AUTOSAR XML (schema 4-0-3)
package /ComponentTypes
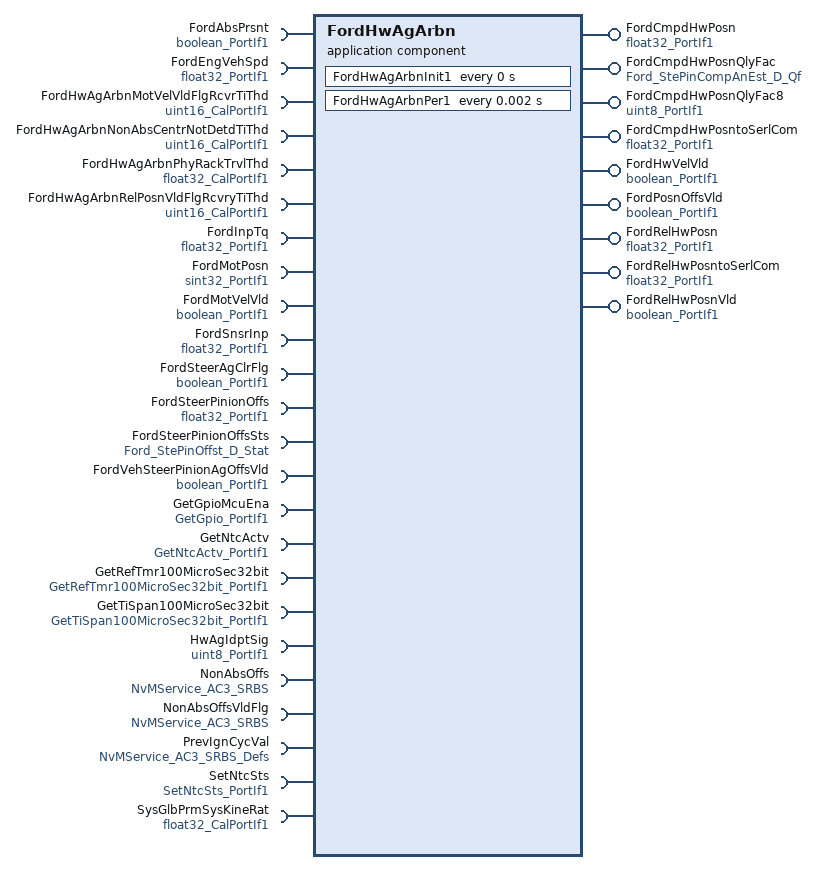
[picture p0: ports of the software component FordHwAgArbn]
  application sw component type FordHwAgArbn
    9 x provide port:
      FordCmpdHwPosn: nonqueued-sender-com-spec{data-element=Val, init-value=0}, provided-interface=float32_PortIf1
      FordCmpdHwPosnQlyFac: nonqueued-sender-com-spec{data-element=Ford_StePinCompAnEst_D_Qf, init-value=1}, provided-interface=Ford_StePinCompAnEst_D_Qf
      FordCmpdHwPosnQlyFac8: nonqueued-sender-com-spec{data-element=Val, init-value=1}, provided-interface=uint8_PortIf1
      FordCmpdHwPosntoSerlCom: nonqueued-sender-com-spec{data-element=Val, init-value=0}, provided-interface=float32_PortIf1
      FordHwVelVld: nonqueued-sender-com-spec{data-element=Logl, init-value=0}, provided-interface=boolean_PortIf1
      FordPosnOffsVld: nonqueued-sender-com-spec{data-element=Logl, init-value=0}, provided-interface=boolean_PortIf1
      FordRelHwPosn: nonqueued-sender-com-spec{data-element=Val, init-value=0}, provided-interface=float32_PortIf1
      FordRelHwPosntoSerlCom: nonqueued-sender-com-spec{data-element=Val, init-value=0}, provided-interface=float32_PortIf1
      FordRelHwPosnVld: nonqueued-sender-com-spec{data-element=Logl, init-value=0}, provided-interface=boolean_PortIf1
    24 x require port:
      FordAbsPrsnt: nonqueued-receiver-com-spec{data-element=Logl, filter=data-filter-type=ALWAYS, init-value=0}, required-interface=boolean_PortIf1
      FordEngVehSpd: nonqueued-receiver-com-spec{data-element=Val, filter=data-filter-type=ALWAYS, init-value=0}, required-interface=float32_PortIf1
      FordHwAgArbnMotVelVldFlgRcvrTiThd: parameter-require-com-spec{init-value=30000, parameter=Val}, required-interface=uint16_CalPortIf1
      FordHwAgArbnNonAbsCentrNotDetdTiThd: parameter-require-com-spec{init-value=30000, parameter=Val}, required-interface=uint16_CalPortIf1
      FordHwAgArbnPhyRackTrvlThd: parameter-require-com-spec{init-value=65535, parameter=Val}, required-interface=float32_CalPortIf1
      FordHwAgArbnRelPosnVldFlgRcvryTiThd: parameter-require-com-spec{init-value=0, parameter=Val}, required-interface=uint16_CalPortIf1
      FordInpTq: nonqueued-receiver-com-spec{data-element=Val, filter=data-filter-type=ALWAYS, init-value=0}, required-interface=float32_PortIf1
      FordMotPosn: nonqueued-receiver-com-spec{data-element=Val, filter=data-filter-type=ALWAYS}, required-interface=sint32_PortIf1
      FordMotVelVld: nonqueued-receiver-com-spec{data-element=Logl, filter=data-filter-type=ALWAYS, init-value=0}, required-interface=boolean_PortIf1
      FordSnsrInp: nonqueued-receiver-com-spec{data-element=Val, filter=data-filter-type=ALWAYS, init-value=0}, required-interface=float32_PortIf1
      FordSteerAgClrFlg: nonqueued-receiver-com-spec{data-element=Logl, filter=data-filter-type=ALWAYS, init-value=0}, required-interface=boolean_PortIf1
      FordSteerPinionOffs: nonqueued-receiver-com-spec{data-element=Val, filter=data-filter-type=ALWAYS, init-value=0}, required-interface=float32_PortIf1
      FordSteerPinionOffsSts: nonqueued-receiver-com-spec{data-element=Ford_StePinOffst_D_Stat, filter=data-filter-type=ALWAYS, init-value=0}, required-interface=Ford_StePinOffst_D_Stat
      FordVehSteerPinionAgOffsVld: nonqueued-receiver-com-spec{data-element=Logl, filter=data-filter-type=ALWAYS, init-value=0}, required-interface=boolean_PortIf1
      GetGpioMcuEna: client-com-spec=Oper, required-interface=GetGpio_PortIf1
      GetNtcActv: client-com-spec=Oper, required-interface=GetNtcActv_PortIf1
      GetRefTmr100MicroSec32bit: client-com-spec=Oper, required-interface=GetRefTmr100MicroSec32bit_PortIf1
      GetTiSpan100MicroSec32bit: client-com-spec=Oper, required-interface=GetTiSpan100MicroSec32bit_PortIf1
      HwAgIdptSig: nonqueued-receiver-com-spec{data-element=Val, filter=data-filter-type=ALWAYS, init-value=2}, required-interface=uint8_PortIf1
      NonAbsOffs: required-com-specs=[EraseBlock, GetErrorStatus, InvalidateNvBlock, ReadBlock, SetRamBlockStatus, WriteBlock], required-interface=NvMService_AC3_SRBS
      NonAbsOffsVldFlg: required-com-specs=[EraseBlock, GetErrorStatus, InvalidateNvBlock, ReadBlock, SetRamBlockStatus, WriteBlock], required-interface=NvMService_AC3_SRBS
      PrevIgnCycVal: required-com-specs=[EraseBlock, GetErrorStatus, InvalidateNvBlock, ReadBlock, RestoreBlockDefaults, SetRamBlockStatus, WriteBlock], required-interface=NvMService_AC3_SRBS_Defs
      SetNtcSts: client-com-spec=Oper, required-interface=SetNtcSts_PortIf1
      SysGlbPrmSysKineRat: parameter-require-com-spec{init-value=22, parameter=Val}, required-interface=float32_CalPortIf1
    behavior FordHwAgArbn_InternalBehavior
      ar-typed-per-instance-memorys:
        14 x data, all with sw-calibration-access=READ-ONLY:
          FirstTranVldFlg: type=boolean
          FordCmpdHwPosnPrev: type=float32
          FordCmpdHwPosnQlyFacPrev: type=Ford_StePinCompAnEst_D_Qf
          FordSteerPinionOffsStsPrev: type=Ford_StePinOffst_D_Stat
          MotVelVldTrueTi: type=uint32
          NoDataExistFlg: type=boolean
          NonAbsCentrNotDetdTi: type=uint32
          NonAbsOffs: type=float32
          NonAbsOffsVldFlg: type=boolean
          PrevIgnCycVal: type=float32
          RelHwPosnPrev: type=float32
          RelHwPosnVld: type=boolean
          RelPosnLossFlg: type=boolean
          RelPosnVldFlgRcvryTi: type=uint32
      timing event FordHwAgArbn_InitEvent: start-on-event=FordHwAgArbnInit1, period=0
      timing event TMT_FordHwAgArbnPer1: start-on-event=FordHwAgArbnPer1, period=0.002
      explicit-inter-runnable-variables:
        data FordSnsrOutp: type=float32, init-value=0
      port-api-options:
        enable-take-address=false, indirect-api=false, port=FordAbsPrsnt
        enable-take-address=false, indirect-api=false, port=FordCmpdHwPosn
        enable-take-address=false, indirect-api=false, port=FordCmpdHwPosnQlyFac
        enable-take-address=false, indirect-api=false, port=FordCmpdHwPosnQlyFac8
        enable-take-address=false, indirect-api=false, port=FordCmpdHwPosntoSerlCom
        enable-take-address=false, indirect-api=false, port=FordEngVehSpd
        enable-take-address=false, indirect-api=false, port=FordHwAgArbnMotVelVldFlgRcvrTiThd
        enable-take-address=false, indirect-api=false, port=FordHwAgArbnNonAbsCentrNotDetdTiThd
        enable-take-address=false, indirect-api=false, port=FordHwAgArbnPhyRackTrvlThd
        enable-take-address=false, indirect-api=false, port=FordHwAgArbnRelPosnVldFlgRcvryTiThd
        enable-take-address=false, indirect-api=false, port=FordHwVelVld
        enable-take-address=false, indirect-api=false, port=FordInpTq
        enable-take-address=false, indirect-api=false, port=FordMotPosn
        enable-take-address=false, indirect-api=false, port=FordMotVelVld
        enable-take-address=false, indirect-api=false, port=FordPosnOffsVld
        enable-take-address=false, indirect-api=false, port=FordRelHwPosn
        enable-take-address=false, indirect-api=false, port=FordRelHwPosntoSerlCom
        enable-take-address=false, indirect-api=false, port=FordRelHwPosnVld
        enable-take-address=false, indirect-api=false, port=FordSnsrInp
        enable-take-address=false, indirect-api=false, port=FordSteerAgClrFlg
        enable-take-address=false, indirect-api=false, port=FordSteerPinionOffs
        enable-take-address=false, indirect-api=false, port=FordSteerPinionOffsSts
        enable-take-address=false, indirect-api=false, port=FordVehSteerPinionAgOffsVld
        enable-take-address=false, indirect-api=false, port=GetGpioMcuEna
        enable-take-address=false, indirect-api=false, port=GetNtcActv
        enable-take-address=false, indirect-api=false, port=GetRefTmr100MicroSec32bit
        enable-take-address=false, indirect-api=false, port=GetTiSpan100MicroSec32bit
        enable-take-address=false, indirect-api=false, port=HwAgIdptSig
        enable-take-address=false, indirect-api=false, port=NonAbsOffs
        enable-take-address=false, indirect-api=false, port=NonAbsOffsVldFlg
        enable-take-address=false, indirect-api=false, port=PrevIgnCycVal
        enable-take-address=false, indirect-api=false, port=SetNtcSts
        enable-take-address=false, indirect-api=false, port=SysGlbPrmSysKineRat
      runnable FordHwAgArbnInit1
        7 x sync call, all with timeout=0:
          SC_GetRefTmr100MicroSec32bit_Oper: operation=GetRefTmr100MicroSec32bit.Oper
          SC_NonAbsOffs_GetErrorStatus: operation=NonAbsOffs.GetErrorStatus
          SC_NonAbsOffs_SetRamBlockStatus: operation=NonAbsOffs.SetRamBlockStatus
          SC_NonAbsOffsVldFlg_GetErrorStatus: operation=NonAbsOffsVldFlg.GetErrorStatus
          SC_NonAbsOffsVldFlg_SetRamBlockStatus: operation=NonAbsOffsVldFlg.SetRamBlockStatus
          SC_PrevIgnCycVal_GetErrorStatus: operation=PrevIgnCycVal.GetErrorStatus
          SC_SetNtcSts_Oper: operation=SetNtcSts.Oper
        written-local-variables:
          access WRITE_FordSnsrOutp: accessed-variable=FordSnsrOutp
      runnable FordHwAgArbnPer1
        data-receive-point-by-arguments:
          11 x access:
            REC_FordAbsPrsnt_Logl: accessed-variable=FordAbsPrsnt.Logl
            REC_FordEngVehSpd_Val_1: accessed-variable=FordEngVehSpd.Val
            REC_FordInpTq_Val: accessed-variable=FordInpTq.Val
            REC_FordMotPosn_Val: accessed-variable=FordMotPosn.Val
            REC_FordMotVelVld_Logl: accessed-variable=FordMotVelVld.Logl
            REC_FordSnsrInp_Val: accessed-variable=FordSnsrInp.Val
            REC_FordSteerAgClrFlg_Logl: accessed-variable=FordSteerAgClrFlg.Logl
            REC_FordSteerPinionOffs_Val: accessed-variable=FordSteerPinionOffs.Val
            REC_FordSteerPinionOffsSts_Ford_StePinOffst_D_Stat: accessed-variable=FordSteerPinionOffsSts.Ford_StePinOffst_D_Stat
            REC_FordVehSteerPinionAgOffsVld_Logl: accessed-variable=FordVehSteerPinionAgOffsVld.Logl
            REC_HwAgIdptSig_Val: accessed-variable=HwAgIdptSig.Val
        data-send-points:
          9 x access:
            SEND_FordCmpdHwPosn_Val: accessed-variable=FordCmpdHwPosn.Val
            SEND_FordCmpdHwPosnQlyFac_Ford_StePinCompAnEst_D_Qf: accessed-variable=FordCmpdHwPosnQlyFac.Ford_StePinCompAnEst_D_Qf
            SEND_FordCmpdHwPosnQlyFac8_Val: accessed-variable=FordCmpdHwPosnQlyFac8.Val
            SEND_FordCmpdHwPosntoSerlCom_Val: accessed-variable=FordCmpdHwPosntoSerlCom.Val
            SEND_FordHwVelVld_Logl: accessed-variable=FordHwVelVld.Logl
            SEND_FordPosnOffsVld_Logl: accessed-variable=FordPosnOffsVld.Logl
            SEND_FordRelHwPosn_Val: accessed-variable=FordRelHwPosn.Val
            SEND_FordRelHwPosntoSerlCom_Val: accessed-variable=FordRelHwPosntoSerlCom.Val
            SEND_FordRelHwPosnVld_Logl: accessed-variable=FordRelHwPosnVld.Logl
        read-local-variables:
          access READ_FordSnsrOutp: accessed-variable=FordSnsrOutp
        8 x sync call, all with timeout=0:
          SC_GetGpioMcuEna_Oper: operation=GetGpioMcuEna.Oper
          SC_GetNtcActv_Oper: operation=GetNtcActv.Oper
          SC_GetRefTmr100MicroSec32bit_Oper: operation=GetRefTmr100MicroSec32bit.Oper
          SC_GetTiSpan100MicroSec32bit_Oper: operation=GetTiSpan100MicroSec32bit.Oper
          SC_NonAbsOffs_SetRamBlockStatus: operation=NonAbsOffs.SetRamBlockStatus
          SC_NonAbsOffsVldFlg_SetRamBlockStatus: operation=NonAbsOffsVldFlg.SetRamBlockStatus
          SC_PrevIgnCycVal_SetRamBlockStatus: operation=PrevIgnCycVal.SetRamBlockStatus
          SC_SetNtcSts_Oper: operation=SetNtcSts.Oper
      swc service dependency NvmNonAbsOffs: assigned-datas=role-based-data-assignment={role=ramBlock, used-data-element=NonAbsOffs}, assigned-ports=role-based-port-assignment={port-prototype=NonAbsOffs, role=NvMService_AC3_SRBS}
        service-needs:
          nv block needs NvmNonAbsOffs: n-data-sets=0, reliability=ERROR-DETECTION, resistant-to-changed-sw=true, restore-at-start=true, store-at-shutdown=true, write-only-once=false
      swc service dependency NvmNonAbsOffsVldFlg: assigned-datas=role-based-data-assignment={role=ramBlock, used-data-element=NonAbsOffsVldFlg}, assigned-ports=role-based-port-assignment={port-prototype=NonAbsOffsVldFlg, role=NvMService_AC3_SRBS}
        service-needs:
          nv block needs NvmNonAbsOffsVldFlg: n-data-sets=0, reliability=ERROR-DETECTION, resistant-to-changed-sw=true, restore-at-start=true, store-at-shutdown=true
      swc service dependency NvmPrevIgnCycVal: assigned-ports=role-based-port-assignment={port-prototype=PrevIgnCycVal, role=NvMService_AC3_SRBS_Defs}
        assigned-datas:
          role=ramBlock, used-data-element=PrevIgnCycVal
          role=defaultValue, used-parameter-element=PrevIgnCycValDft
        service-needs:
          nv block needs NvmPrevIgnCycVal: n-data-sets=0, reliability=ERROR-DETECTION, resistant-to-changed-sw=true, restore-at-start=true, store-at-shutdown=true
      shared-parameters:
        parameter data prototype PrevIgnCycValDft: sw-calibration-access=READ-WRITE, type=float32, init-value=0
  swc implementation FordHwAgArbn_Implementation: behavior=FordHwAgArbn_InternalBehavior
    code-descriptors:
      code Default: artifact-descriptors=autosar-engineering-object={short-label=Default, category=SWSRC}
